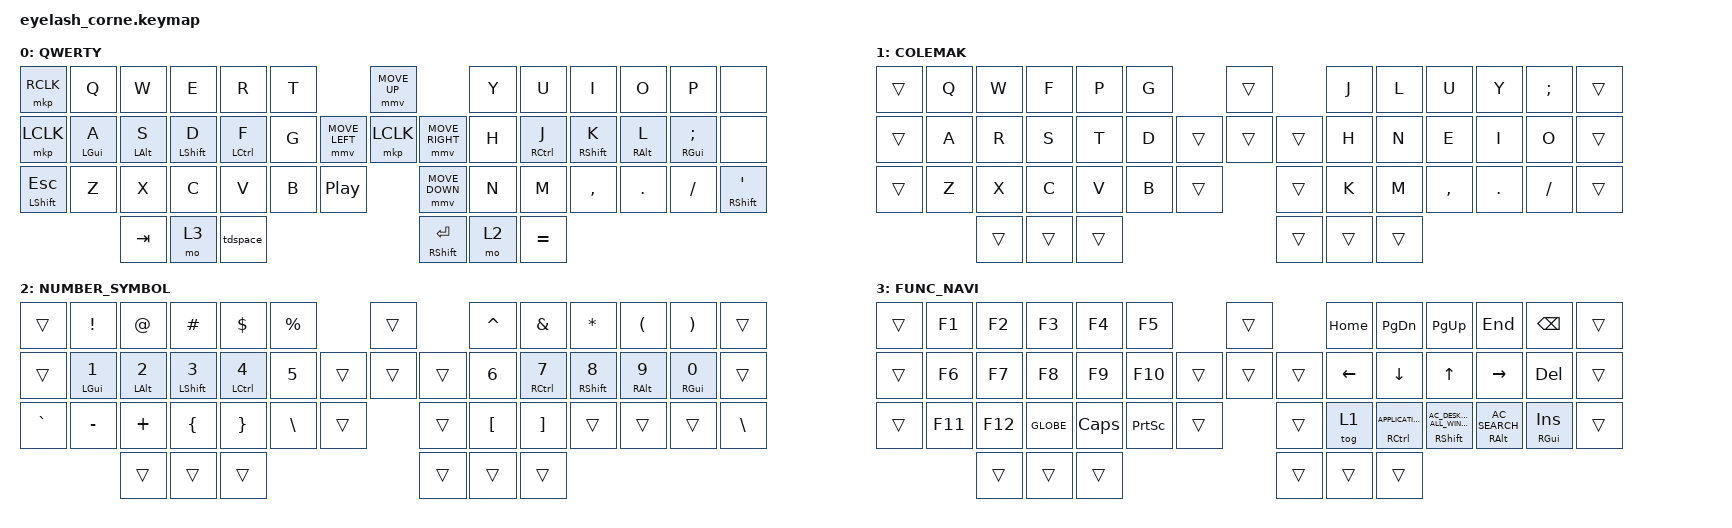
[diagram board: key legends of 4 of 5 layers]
#define ZMK_POINTING_DEFAULT_MOVE_VAL 1200  // 600
#define ZMK_POINTING_DEFAULT_SCRL_VAL 25   // 10

#include <input/processors.dtsi>
#include <zephyr/dt-bindings/input/input-event-codes.h>
#include <behaviors.dtsi>
#include <dt-bindings/zmk/bt.h>
#include <dt-bindings/zmk/ext_power.h>
#include <dt-bindings/zmk/keys.h>
#include <dt-bindings/zmk/outputs.h>
#include <dt-bindings/zmk/pointing.h>
#include <dt-bindings/zmk/rgb.h>

#define DEFAULT 0
#define COLEMAK 1
#define LOWER   2
#define RAISE   3
#define MISC    4

// ============================================
// Home Row Mods - Cross-hand positional hold-tap
// ============================================
// Eyelash Corne layout (48 positions):
// Row 0:  0   1   2   3   4   5  6   7   8   9  10  11  12
// Row 1: 13  14  15  16  17  18  19  20  21  22  23  24  25  26  27
// Row 2: 28  29  30  31  32  33  34  35  36  37  38  39  40  41
// Thumbs: 42  43  44      45  46  47

#define KEYS_L 1 2 3 4 5 14 15 16 17 18 28 29 30 31 32 33
#define KEYS_R 7 8 9 10 11 22 23 24 25 26 36 37 38 39 40 41
#define THUMBS 42 43 44 45 46 47

&mmv_input_listener { input-processors = <&zip_xy_scaler 2 1>; };

&msc_input_listener { input-processors = <&zip_scroll_scaler 2 1>; };

&msc {
    acceleration-exponent = <1>;      // 0
    time-to-max-speed-ms = <100>;       // 300
    delay-ms = <0>;                   // 0
};

&mmv {
    time-to-max-speed-ms = <500>;
    acceleration-exponent = <1>;
    trigger-period-ms = <16>;
};

&mt {
    flavor = "balanced";
    tapping-term-ms = <200>;
};

/ {
    behaviors {
        hml: home_row_mod_left {
            compatible = "zmk,behavior-hold-tap";
            #binding-cells = <2>;
            flavor = "balanced";
            tapping-term-ms = <200>;
            quick-tap-ms = <175>;
            require-prior-idle-ms = <150>;
            bindings = <&kp>, <&kp>;

            hold-trigger-key-positions = <KEYS_R THUMBS>;
            hold-trigger-on-release;
        };

        hmr: home_row_mod_right {
            compatible = "zmk,behavior-hold-tap";
            #binding-cells = <2>;
            flavor = "balanced";
            tapping-term-ms = <200>;
            quick-tap-ms = <175>;
            require-prior-idle-ms = <150>;
            bindings = <&kp>, <&kp>;

            hold-trigger-key-positions = <KEYS_L THUMBS>;
            hold-trigger-on-release;
        };

        td_esc_caps: td_esc_caps {
            compatible = "zmk,behavior-tap-dance";
            label = "TD_ESC_CAPS";
            #binding-cells = <0>;
            tapping-term-ms = <150>;
            bindings = <&mt LEFT_ALT ESCAPE>, <&kp CAPSLOCK>;
        };

        tdspace: tdspace {
            compatible = "zmk,behavior-tap-dance";
            label = "TDSPACE";
            #binding-cells = <0>;
            bindings = <&mt LGUI SPACE>, <&kp SPACE>;

            tapping-term-ms = <100>;
        };
    };

    rgb_encoder: rgb_encoder {
        compatible = "zmk,behavior-sensor-rotate";
        #sensor-binding-cells = <0>;
        bindings = <&rgb_ug RGB_BRI>, <&rgb_ug RGB_BRD>;
    };

    scroll_encoder: scroll_encoder {
        compatible = "zmk,behavior-sensor-rotate";
        #sensor-binding-cells = <0>;
        bindings = <&msc SCRL_DOWN>, <&msc SCRL_UP>;

        tap-ms = <100>;
    };

    combos {
        compatible = "zmk,combos";

        space {
            bindings = <&kp SPACE>;
            key-positions = <45 46>;
            timeout-ms = <30>;
            layers = <0 1>;
        };

        tab {
            bindings = <&kp TAB>;
            key-positions = <1 2>;
            timeout-ms = <30>;
            layers = <0 1>;
        };

        backspace {
            bindings = <&kp BACKSPACE>;
            key-positions = <11 10>;
            timeout-ms = <30>;
            layers = <0 1>;
        };
    };

    keymap {
        compatible = "zmk,keymap";

        default_layer {
            display-name = "QWERTY";
            bindings = <
&mkp RCLK          &kp Q        &kp W        &kp E          &kp R         &kp T                                         &mmv MOVE_UP                     &kp Y            &kp U         &kp I          &kp O        &kp P            &none
&mkp LCLK          &hml LGUI A  &hml LALT S  &hml LSHIFT D  &hml LCTRL F  &kp G                         &mmv MOVE_LEFT  &mkp LCLK       &mmv MOVE_RIGHT  &kp H            &hmr RCTRL J  &hmr RSHIFT K  &hmr RALT L  &hmr RGUI SEMI   &none
&mt LSHIFT ESCAPE  &kp Z        &kp X        &kp C          &kp V         &kp B     &kp C_PLAY_PAUSE                    &mmv MOVE_DOWN                   &kp N            &kp M         &kp COMMA      &kp DOT      &kp FSLH         &mt RSHIFT SINGLE_QUOTE
                                 &kp TAB       &mo 3         &tdspace                                                                       &mt RSHIFT ENTER  &mo 2        &kp EQUAL
            >;

            sensor-bindings = <&scroll_encoder>;
        };

        colemak {
            bindings = <
&trans  &kp Q  &kp W  &kp F   &kp P   &kp G                       &trans          &kp J   &kp L   &kp U      &kp Y       &kp SEMI       &trans
&trans  &kp A  &kp R  &kp S   &kp T   &kp D               &trans  &trans  &trans  &kp H   &kp N   &kp E      &kp I       &kp O          &trans
&trans  &kp Z  &kp X  &kp C   &kp V   &kp B     &trans            &trans          &kp K   &kp M   &kp COMMA  &kp DOT     &kp FSLH       &trans
                      &trans  &trans  &trans                                     &trans  &trans  &trans
            >;

            sensor-bindings = <&scroll_encoder>;
            label = "COLEMAK";
        };

        lower_layer {
            display-name = "NUMBER_SYMBOL";
            bindings = <
&trans     &kp EXCL      &kp AT        &kp HASH        &kp DLLR       &kp PRCNT                                &trans                          &kp CARET       &kp AMPS        &kp ASTRK       &kp LPAR      &kp RPAR      &trans
&trans     &hml LGUI N1  &hml LALT N2  &hml LSHIFT N3  &hml LCTRL N4  &kp N5                     &trans          &trans          &trans          &kp N6         &hmr RCTRL N7  &hmr RSHIFT N8  &hmr RALT N9  &hmr RGUI N0  &trans
&kp GRAVE  &kp MINUS     &kp PLUS      &kp LBRC        &kp RBRC       &kp BSLH     &trans                    &trans                          &kp LBKT        &kp RBKT        &trans        &trans        &trans       &kp BACKSLASH
                                        &trans          &trans         &trans                                                                  &trans           &trans           &trans
            >;

            sensor-bindings = <&inc_dec_kp C_BRIGHTNESS_INC C_BRIGHTNESS_DEC>;
        };

        raise_layer {
            display-name = "FUNC_NAVI";
            bindings = <
&trans  &kp F1        &kp F2        &kp F3          &kp F4         &kp F5                                      &trans          &kp HOME      &kp PAGE_DOWN  &kp PAGE_UP                                &kp END                     &kp BSPC    &trans
&trans  &kp F6        &kp F7        &kp F8          &kp F9         &kp F10                         &trans          &trans        &trans        &kp LEFT                                   &kp DOWN                    &kp UP_ARROW  &kp RIGHT   &kp DELETE  &trans
&trans  &kp F11       &kp F12       &kp GLOBE       &kp CAPSLOCK   &kp PRINTSCREEN  &trans                     &trans          &tog 1        &hmr RIGHT_CONTROL K_APPLICATION         &hmr RIGHT_SHIFT C_AC_DESKTOP_SHOW_ALL_WINDOWS  &hmr RIGHT_ALT C_AC_SEARCH  &hmr RIGHT_GUI INS  &trans
                          &trans     &trans         &trans                                                                             &trans    &trans       &trans
            >;

            sensor-bindings = <&inc_dec_kp C_VOL_UP C_VOL_DN>;
        };

        misc {
            display-name = "MISC";
            bindings = <
&none  &bt BT_SEL 0       &bt BT_SEL 1   &bt BT_SEL 2       &bt BT_SEL 3  &bt BT_SEL 4                                     &trans          &none            &none            &none            &none            &bt BT_CLR
&none  &kp C_VOL_UP       &kp C_BRI_INC  &soft_off          &out OUT_TOG  &sys_reset                     &trans          &trans          &trans          &rgb_ug RGB_SPI  &rgb_ug RGB_SAI  &rgb_ug RGB_HUI  &rgb_ug RGB_BRI  &rgb_ug RGB_EFF  &none
&none  &kp C_VOLUME_DOWN  &kp C_BRI_DEC  &ext_power EP_TOG  &none         &bootloader   &trans                           &trans          &rgb_ug RGB_SPD  &rgb_ug RGB_SAD  &rgb_ug RGB_HUD  &rgb_ug RGB_BRD  &rgb_ug RGB_TOG  &none
                                            &none              &none         &none                                                                           &none            &none            &none
            >;

            sensor-bindings = <&rgb_encoder>;
        };
    };

    conditional_layers {
        compatible = "zmk,conditional-layers";

        misc {
            if-layers = <2 3>;
            then-layer = <4>;
        };
    };
};
